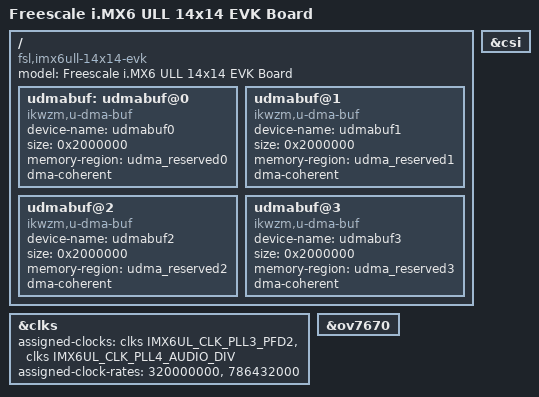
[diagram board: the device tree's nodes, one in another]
// SPDX-License-Identifier: (GPL-2.0 OR MIT)
//
// Copyright (C) 2016 Freescale Semiconductor, Inc.

/dts-v1/;

#include "imx6ull.dtsi"
#include "imx6ul-14x14-evk.dtsi"

/ {
	model = "Freescale i.MX6 ULL 14x14 EVK Board";
	compatible = "fsl,imx6ull-14x14-evk", "fsl,imx6ull";
};

&clks {
	assigned-clocks = <&clks IMX6UL_CLK_PLL3_PFD2>,
			  <&clks IMX6UL_CLK_PLL4_AUDIO_DIV>;
	assigned-clock-rates = <320000000>, <786432000>;
};

&csi {
	status = "okay";
};

&ov7670 {
	status = "okay";
};

/ {
	udmabuf: udmabuf@0 {
		compatible = "ikwzm,u-dma-buf";
		device-name = "udmabuf0";
		size = <0x2000000>;
		memory-region = <&udma_reserved0>;
		dma-coherent;
	};
	udmabuf@1 {
		compatible = "ikwzm,u-dma-buf";
		device-name = "udmabuf1";

		size = <0x2000000>;
		memory-region = <&udma_reserved1>;
		dma-coherent;
	};
	udmabuf@2 {
		compatible = "ikwzm,u-dma-buf";
		device-name = "udmabuf2";

		size = <0x2000000>;
		memory-region = <&udma_reserved2>;
		dma-coherent;
	};
	udmabuf@3 {
		compatible = "ikwzm,u-dma-buf";
		device-name = "udmabuf3";

		size = <0x2000000>;
		memory-region = <&udma_reserved3>;
		dma-coherent;
	};
};

/delete-node/ &sim2;
